# MCAN register map
Vendor: Texas Instruments
Registers are 32-bit, access per field, no defined reset value unless marked. A register's access mark holds for its fields unless they carry their own. Offsets are as the file gives them; [hi:lo] are bit positions.

## MCAN (part 2 of 2)
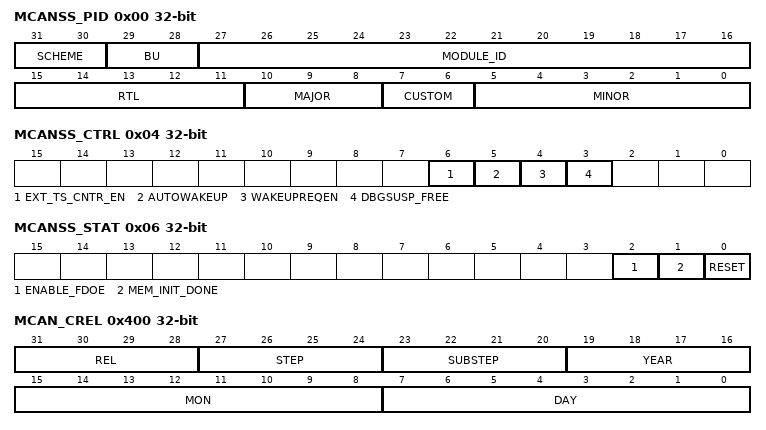
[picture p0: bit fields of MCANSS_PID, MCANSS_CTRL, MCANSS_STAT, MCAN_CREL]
0x00 MCANSS_PID ro — MCAN Subsystem Revision Register
  [31:30] SCHEME — PID Register Scheme
  [29:28] BU — Business Unit: 0x2 = Processors
  [27:16] MODULE_ID — Module Identification Number
  [15:11] RTL — RTL revision. Will vary depending on release
  [10:8] MAJOR — Major Revision of the MCAN Subsystem
  [7:6] CUSTOM — Custom Value
  [5:0] MINOR — Minor Revision of the MCAN Subsystem
0x04 MCANSS_CTRL — MCAN Subsystem Control Register
  [6] EXT_TS_CNTR_EN rw — External Timestamp Counter Enable. #br# 0 External timestamp counter disabled #br# 1 External timestamp counter enabled
  [5] AUTOWAKEUP rw — Automatic Wakeup Enable. Enables the MCANSS to automatically clear the MCAN CCCR.INIT bit, fully waking the MCAN up, on an enabled wakeup request. #br# 0 Disable the automatic write to CCCR.INIT #br# 1 Enable the automatic write to CCCR.INIT
  [4] WAKEUPREQEN rw — Wakeup Request Enable. Enables the MCANSS to wakeup on CAN RXD activity. #br# 0 Disable wakeup request #br# 1 Enables wakeup request
  [3] DBGSUSP_FREE rw — Debug Suspend Free Bit. Enables debug suspend. #br# 0 Disable debug suspend #br# 1 Enable debug suspend
0x06 MCANSS_STAT ro — MCAN Subsystem Status Register
  [2] ENABLE_FDOE — Flexible Datarate Operation Enable. Determines whether CAN FD operation may be enabled via the MCAN core CCCR.FDOE bit (bit 8) or if only standard CAN operation is possible with this instance of the MCAN. #br# 0 MCAN is only capable of standard CAN communication #br# 1 MCAN may be configured to perform CAN FD communication
  [1] MEM_INIT_DONE — Memory Initialization Done. #br# 0 Message RAM initialization is in progress #br# 1 Message RAM is initialized for use
  [0] RESET — Soft Reset Status. #br# 0 Not in reset #br# 1 Reset is in progress
0x0C MCANSS_ICS — MCAN Subsystem Interrupt Clear Shadow Register
  [0] EXT_TS_CNTR_OVFL rw — External Timestamp Counter Overflow Interrupt Status Clear. Reads always return a 0. #br# 0 Write of '0' has no effect #br# 1 Write of '1' clears the MCANSS_IRS.EXT_TS_CNTR_OVFL bit
0x10 MCANSS_IRS — MCAN Subsystem Interrupt Raw Satus Register
  [0] EXT_TS_CNTR_OVFL rw — External Timestamp Counter Overflow Interrupt Status. This bit is set by HW or by a SW write of '1'. To clear, use the MCANSS_ICS.EXT_TS_CNTR_OVFL bit. #br# 0 External timestamp counter has not overflowed #br# 1 External timestamp counter has overflowed #br# #br#When this bit is set to '1' by HW or SW, the MCANSS_EXT_TS_UNSERVICED_INTR_CNTR.EXT_TS_INTR_CNTR bit field will increment by 1.
0x14 MCANSS_IECS — MCAN Subsystem Interrupt Enable Clear Shadow Register
  [0] EXT_TS_CNTR_OVFL rw — External Timestamp Counter Overflow Interrupt Enable Clear. Reads always return a 0. #br# 0 Write of '0' has no effect #br# 1 Write of '1' clears the MCANSS_IES.EXT_TS_CNTR_OVFL bit
0x18 MCANSS_IE — MCAN Subsystem Interrupt Enable Register
  [0] EXT_TS_CNTR_OVFL rw — External Timestamp Counter Overflow Interrupt Enable. A write of '0' has no effect. A write of '1' sets the MCANSS_IES.EXT_TS_CNTR_OVFL bit.
0x1C MCANSS_IES ro — MCAN Subsystem Interrupt Enable Status
  [0] EXT_TS_CNTR_OVFL — External Timestamp Counter Overflow Interrupt Enable Status. To set, use the CANSS_IE.EXT_TS_CNTR_OVFL bit. To clear, use the MCANSS_IECS.EXT_TS_CNTR_OVFL bit. #br# 0 External timestamp counter overflow interrupt is not enabled #br# 1 External timestamp counter overflow interrupt is enabled
0x20 MCANSS_EOI — MCAN Subsystem End of Interrupt
  [7:0] EOI rw — End of Interrupt. A write to this register will clear the associated interrupt. If the unserviced interrupt counter is > 1, another interrupt is generated. #br# 0x00 External TS Interrupt is cleared #br# 0x01 MCAN[0] interrupt is cleared #br# 0x02 MCAN[1] interrupt is cleared #br# Other writes are ignored.
0x24 MCANSS_EXT_TS_PRESCALER — MCAN Subsystem External Timestamp Prescaler 0
  [23:0] PRESCALER rw — External Timestamp Prescaler Reload Value. The external timestamp count rate is the host (system) clock rate divided by this value, except in the case of 0. A zero value in this bit field will act identically to a value of 0x000001.
0x28 MCANSS_EXT_TS_UNSERVICED_INTR_CNTR ro — MCAN Subsystem External Timestamp Unserviced Interrupts Counter
  [4:0] EXT_TS_INTR_CNTR — External Timestamp Counter Unserviced Rollover Interrupts. If this value is > 1, an MCANSS_EOI write of '1' to bit 0 will issue another interrupt. #br# #br#The status of this bit field is affected by the MCANSS_IRS.EXT_TS_CNTR_OVFL bit field.
0x400 MCAN_CREL ro — MCAN Core Release Register
  [31:28] REL — Core Release. One digit, BCD-coded.
  [27:24] STEP — Step of Core Release. One digit, BCD-coded.
  [23:20] SUBSTEP — Sub-Step of Core Release. One digit, BCD-coded.
  [19:16] YEAR — Time Stamp Year. One digit, BCD-coded.
  [15:8] MON — Time Stamp Month. Two digits, BCD-coded.
  [7:0] DAY — Time Stamp Day. Two digits, BCD-coded.
0x404 MCAN_ENDN ro — MCAN Endian Register
  [31:0] ETV — Endianess Test Value. Reading the constant value maintained in this register allows software to determine the endianess of the host CPU.
0x408 MCAN_CUST ro — MCAN Customer Register
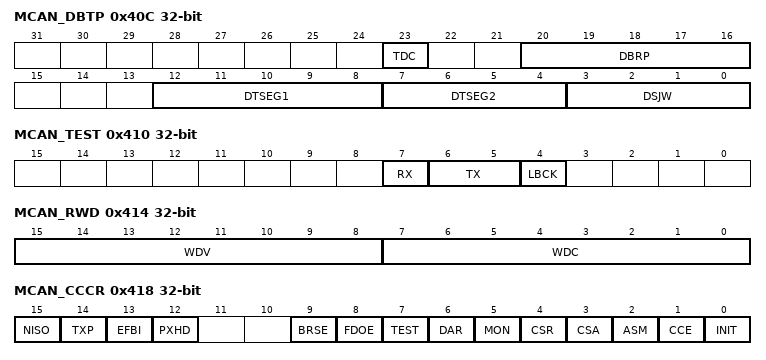
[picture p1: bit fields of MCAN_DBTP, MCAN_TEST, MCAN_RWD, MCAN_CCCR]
0x40C MCAN_DBTP — This register is only writable if bits CCCR.CCE and CCCR.INIT are set. The CAN bit time may be programed in the range of 4 to 49 time quanta. The CAN time quantum may be programmed in the range of 1 to 32 m_can_cclk periods. tq = (DBRP + 1) mtq. #br# #br#DTSEG1 is the sum of Prop_Seg and Phase_Seg1. DTSEG2 is Phase_Seg2. #br# #br#Therefore the length of the bit time is (programmed values) [DTSEG1 + DTSEG2 + 3] tq or (functional values) [Sync_Seg + Prop_Seg + Phase_Seg1 + Phase_Seg2] tq. #br# #br#The Information Processing Time (IPT) is zero, meaning the data for the next bit is available at the first clock edge after the sample point.
  [23] TDC rw — Transmitter Delay Compensation #br# 0 Transmitter Delay Compensation disabled #br# 1 Transmitter Delay Compensation enabled #br# #br#+I107
  [20:16] DBRP rw — Data Bit Rate Prescaler. The value by which the oscillator frequency is divided for generating the bit time quanta. The bit time is built up from a multiple of this quanta. Valid values for the Bit Rate Prescaler are 0 to 31. The actual interpretation by the hardware of this value is such that one more than the value programmed here is used. #br# #br#Qualified Write is possible only with CCCR.CCE='1' and CCCR.INIT='1'.
  [12:8] DTSEG1 rw — Data Time Segment Before Sample Point. Valid values are 0 to 31. The actual interpretation by the hardware of this value is such that one more than the programmed value is used. #br# #br#Qualified Write is possible only with CCCR.CCE='1' and CCCR.INIT='1'.
  [7:4] DTSEG2 rw — Data Time Segment After Sample Point. Valid values are 0 to 15. The actual interpretation by the hardware of this value is such that one more than the programmed value is used. #br# #br#Qualified Write is possible only with CCCR.CCE='1' and CCCR.INIT='1'.
  [3:0] DSJW rw — Data Resynchronization Jump Width. Valid values are 0 to 15. The actual interpretation by the hardware of this value is such that one more than the value programmed here is used. #br# #br#Qualified Write is possible only with CCCR.CCE='1' and CCCR.INIT='1'.
0x410 MCAN_TEST — Write access to the Test Register has to be enabled by setting bit CCCR.TEST to '1'. All Test Register functions are set to their reset values when bit CCCR.TEST is reset. #br# #br#Loop Back Mode and software control of the internal CAN TX pin are hardware test modes. Programming of #br#TX != "00" may disturb the message transfer on the CAN bus.
  [7] RX ro — Receive Pin. Monitors the actual value of the CAN receive pin. #br# 0 The CAN bus is dominant (CAN RX pin = '0') #br# 1 The CAN bus is recessive (CAN RX pin = '1')
  [6:5] TX rw — Control of Transmit Pin #br# 00 CAN TX pin controlled by the CAN Core, updated at the end of the CAN bit time #br# 01 Sample Point can be monitored at CAN TX pin #br# 10 Dominant ('0') level at CAN TX pin #br# 11 Recessive ('1') at CAN TX pin #br# #br#Qualified Write is possible only with CCCR.CCE='1' and CCCR.INIT='1'.
  [4] LBCK rw — Loop Back Mode #br# 0 Reset value, Loop Back Mode is disabled #br# 1 Loop Back Mode is enabled #br# #br#Qualified Write is possible only with CCCR.CCE='1' and CCCR.INIT='1'.
0x414 MCAN_RWD — MCAN RAM Watchdog
  [15:8] WDV ro — Watchdog Value. Actual Message RAM Watchdog Counter Value. #br# #br#The RAM Watchdog monitors the READY output of the Message RAM. A Message RAM access via the MCAN's Generic Controller Interface starts the Message RAM Watchdog Counter with the value configured by the WDC field. The counter is reloaded with WDC when the Message RAM signals successful completion by activating its READY output. In case there is no response from the Message RAM until the counter has counted down to zero, the counter stops and interrupt flag MCAN_IR.WDI is set. The RAM Watchdog Counter is clocked by the host (system) clock.
  [7:0] WDC rw — Watchdog Configuration. Start value of the Message RAM Watchdog Counter. With the reset value of "00" the counter is disabled. #br# #br#Qualified Write is possible only with CCCR.CCE='1' and CCCR.INIT='1'.
0x418 MCAN_CCCR — MCAN CC Control Register
  [15] NISO rw — Non ISO Operation. If this bit is set, the MCAN uses the CAN FD frame format as specified by the Bosch CAN FD Specification V1.0. #br# 0 CAN FD frame format according to ISO 11898-1:2015 #br# 1 CAN FD frame format according to Bosch CAN FD Specification V1.0
  [14] TXP rw — Transmit Pause. If this bit is set, the MCAN pauses for two CAN bit times before starting the next transmission after itself has successfully transmitted a frame. #br# 0 Transmit pause disabled #br# 1 Transmit pause enabled #br# #br#Qualified Write is possible only with CCCR.CCE='1' and CCCR.INIT='1'.
  [13] EFBI rw — Edge Filtering during Bus Integration #br# 0 Edge filtering disabled #br# 1 Two consecutive dominant tq required to detect an edge for hard synchronization #br# #br#Qualified Write is possible only with CCCR.CCE='1' and CCCR.INIT='1'.
  [12] PXHD rw — Protocol Exception Handling Disable #br# 0 Protocol exception handling enabled #br# 1 Protocol exception handling disabled #br#Note: When protocol exception handling is disabled, the MCAN will transmit an error frame when it detects a protocol exception condition. #br# #br#Qualified Write is possible only with CCCR.CCE='1' and CCCR.INIT='1'.
  [9] BRSE rw — Bit Rate Switch Enable #br# 0 Bit rate switching for transmissions disabled #br# 1 Bit rate switching for transmissions enabled #br#Note: When CAN FD operation is disabled FDOE = '0', BRSE is not evaluated. #br# #br#Qualified Write is possible only with CCCR.CCE='1' and CCCR.INIT='1'.
  [8] FDOE rw — Flexible Datarate Operation Enable #br# 0 FD operation disabled #br# 1 FD operation enabled #br# #br#Qualified Write is possible only with CCCR.CCE='1' and CCCR.INIT='1'.
  [7] TEST rw — Test Mode Enable #br# 0 Normal operation, register TEST holds reset values #br# 1 Test Mode, write access to register TEST enabled #br# #br#Qualified Write 1 to Set is possible only with CCCR.CCE='1' and CCCR.INIT='1'.
  [6] DAR rw — Disable Automatic Retransmission #br# 0 Automatic retransmission of messages not transmitted successfully enabled #br# 1 Automatic retransmission disabled #br# #br#Qualified Write is possible only with CCCR.CCE='1' and CCCR.INIT='1'.
  [5] MON rw — Bus Monitoring Mode. Bit MON can only be set by SW when both CCE and INIT are set to '1'. The bit can be reset by SW at any time. #br# 0 Bus Monitoring Mode is disabled #br# 1 Bus Monitoring Mode is enabled #br# #br#Qualified Write 1 to Set is possible only with CCCR.CCE='1' and CCCR.INIT='1'.
  [4] CSR rw — Clock Stop Request #br# 0 No clock stop is requested #br# 1 Clock stop requested. When clock stop is requested, first INIT and then CSA will be set after all pending transfer requests have been completed and the CAN bus reached idle.
  [3] CSA ro — Clock Stop Acknowledge #br# 0 No clock stop acknowledged #br# 1 MCAN may be set in power down by stopping the Host and CAN clocks
  [2] ASM rw — Restricted Operation Mode. Bit ASM can only be set by SW when both CCE and INIT are set to '1'. The bit can be reset by SW at any time. #br# 0 Normal CAN operation #br# 1 Restricted Operation Mode active #br# #br#Qualified Write 1 to Set is possible only with CCCR.CCE='1' and CCCR.INIT='1'.
  [1] CCE rw — Configuration Change Enable #br# 0 The CPU has no write access to the protected configuration registers #br# 1 The CPU has write access to the protected configuration registers (while CCCR.INIT = '1') #br# #br#Qualified Write is possible only with CCCR.CCE='1' and CCCR.INIT='1'.
  [0] INIT rw — Initialization #br# 0 Normal Operation #br# 1 Initialization is started #br#Note: Due to the synchronization mechanism between the two clock domains, there may be a delay until the value written to INIT can be read back. Therefore the programmer has to assure that the previous value written to INIT has been accepted by reading INIT before setting INIT to a new value.
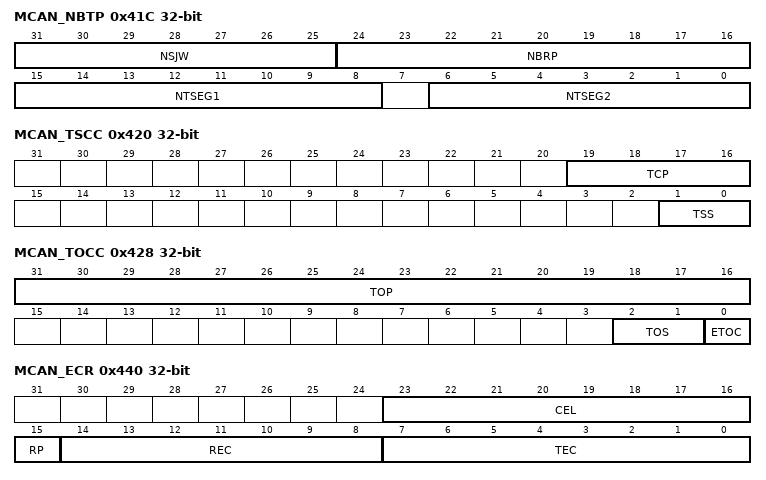
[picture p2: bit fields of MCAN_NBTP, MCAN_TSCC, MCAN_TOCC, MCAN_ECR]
0x41C MCAN_NBTP — This register is only writable if bits CCCR.CCE and CCCR.INIT are set. The CAN bit time may be programed in the range of 4 to 385 time quanta. The CAN time quantum may be programmed in the range of 1 to 512 m_can_cclk periods. tq = (NBRP + 1) mtq. #br# #br#NTSEG1 is the sum of Prop_Seg and Phase_Seg1. NTSEG2 is Phase_Seg2. #br# #br#Therefore the length of the bit time is (programmed values) [NTSEG1 + NTSEG2 + 3] tq or (functional values) [Sync_Seg + Prop_Seg + Phase_Seg1 + Phase_Seg2] tq. #br# #br#The Information Processing Time (IPT) is zero, meaning the data for the next bit is available at the first clock edge after the sample point. #br# #br#Note: With a CAN clock of 8 MHz, the reset value of 0x06000A03 configures the MCAN for a bit rate of 500 kBit/s.
  [31:25] NSJW rw — Nominal (Re)Synchronization Jump Width. Valid values are 0 to 127. The actual interpretation by the hardware of this value is such that one more than the value programmed here is used. #br# #br#Qualified Write is possible only with CCCR.CCE='1' and CCCR.INIT='1'.
  [24:16] NBRP rw — Nominal Bit Rate Prescaler. The value by which the oscillator frequency is divided for generating the bit time quanta. The bit time is built up from a multiple of this quanta. Valid values for the Bit Rate Prescaler are 0 to 511. The actual interpretation by the hardware of this value is such that one more than the value programmed here is used. #br# #br#Qualified Write is possible only with CCCR.CCE='1' and CCCR.INIT='1'.
  [15:8] NTSEG1 rw — Nominal Time Segment Before Sample Point. Valid values are 1 to 255. The actual interpretation by the hardware of this value is such that one more than the programmed value is used. #br# #br#Qualified Write is possible only with CCCR.CCE='1' and CCCR.INIT='1'.
  [6:0] NTSEG2 rw — Nominal Time Segment After Sample Point. Valid values are 1 to 127. The actual interpretation by the hardware of this value is such that one more than the programmed value is used. #br# #br#Qualified Write is possible only with CCCR.CCE='1' and CCCR.INIT='1'.
0x420 MCAN_TSCC — MCAN Timestamp Counter Configuration
  [19:16] TCP rw — Timestamp Counter Prescaler. Configures the timestamp and timeout counters time unit in multiples of CAN bit times. Valid values are 0 to 15. The actual interpretation by the hardware of this value is such that one more than the value programmed here is used. #br# #br#Note: With CAN FD an external counter is required for timestamp generation (TSS = "10"). #br# #br#Qualified Write is possible only with CCCR.CCE='1' and CCCR.INIT='1'.
  [1:0] TSS rw — Timestamp Select #br# 00 Timestamp counter value always 0x0000 #br# 01 Timestamp counter value incremented according to TCP #br# 10 External timestamp counter value used #br# 11 Same as "00" #br# #br#Qualified Write is possible only with CCCR.CCE='1' and CCCR.INIT='1'.
0x424 MCAN_TSCV — MCAN Timestamp Counter Value
  [15:0] TSC rw — Timestamp Counter. The internal/external Timestamp Counter value is captured on start of frame (both Rx and Tx). When TSCC.TSS = "01", the Timestamp Counter is incremented in multiples of CAN bit times, [1...16], depending on the configuration of TSCC.TCP. A wrap around sets interrupt flag IR.TSW. Write access resets the counter to zero. When TSCC.TSS = "10", TSC reflects the External Timestamp Counter value, and a write access has no impact. #br# #br#Note: A "wrap around" is a change of the Timestamp Counter value from non-zero to zero not #br#caused by write access to MCAN_TSCV.
0x428 MCAN_TOCC — MCAN Timeout Counter Configuration
  [31:16] TOP rw — Timeout Period. Start value of the Timeout Counter (down-counter). Configures the Timeout Period. #br# #br#Qualified Write is possible only with CCCR.CCE='1' and CCCR.INIT='1'.
  [2:1] TOS rw — Timeout Select. When operating in Continuous mode, a write to TOCV presets the counter to the value configured by TOCC.TOP and continues down-counting. When the Timeout Counter is controlled by one of the FIFOs, an empty FIFO presets the counter to the value configured by TOCC.TOP. Down-counting is started when the first FIFO element is stored. #br# 00 Continuous operation #br# 01 Timeout controlled by Tx Event FIFO #br# 10 Timeout controlled by Rx FIFO 0 #br# 11 Timeout controlled by Rx FIFO 1 #br# #br#Qualified Write is possible only with CCCR.CCE='1' and CCCR.INIT='1'.
  [0] ETOC rw — Enable Timeout Counter #br# 0 Timeout Counter disabled #br# 1 Timeout Counter enabled #br# #br#Qualified Write is possible only with CCCR.CCE='1' and CCCR.INIT='1'.
0x42C MCAN_TOCV — MCAN Timeout Counter Value
  [15:0] TOC rw — Timeout Counter. The Timeout Counter is decremented in multiples of CAN bit times, [1...16], depending on the configuration of TSCC.TCP. When decremented to zero, interrupt flag IR.TOO is set and the Timeout Counter is stopped. Start and reset/restart conditions are configured via TOCC.TOS.
0x440 MCAN_ECR ro — MCAN Error Counter Register
  [23:16] CEL — CAN Error Logging. The counter is incremented each time when a CAN protocol error causes the Transmit Error Counter or the Receive Error Counter to be incremented. It is reset by read access to CEL. The counter stops at 0xFF; the next increment of TEC or REC sets interrupt flag IR.ELO. #br# #br#Note: When CCCR.ASM is set, the CAN protocol controller does not increment TEC and REC when a CAN protocol error is detected, but CEL is still incremented.
  [15] RP — Receive Error Passive #br# 0 The Receive Error Counter is below the error passive level of 128 #br# 1 The Receive Error Counter has reached the error passive level of 128
  [14:8] REC — Receive Error Counter. Actual state of the Receive Error Counter, values between 0 and 127. #br# #br#Note: When CCCR.ASM is set, the CAN protocol controller does not increment TEC and REC when a CAN protocol error is detected, but CEL is still incremented.
  [7:0] TEC — Transmit Error Counter. Actual state of the Transmit Error Counter, values between 0 and 255. #br# #br#Note: When CCCR.ASM is set, the CAN protocol controller does not increment TEC and REC when a CAN protocol error is detected, but CEL is still incremented.
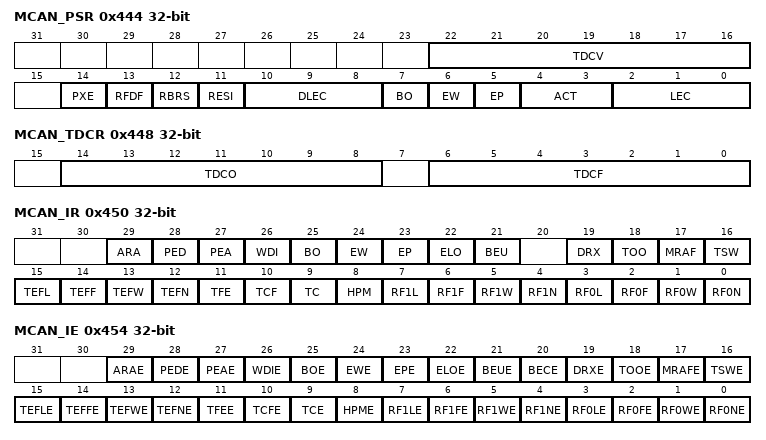
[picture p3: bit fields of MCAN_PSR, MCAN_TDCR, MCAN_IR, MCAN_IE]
0x444 MCAN_PSR ro — MCAN Protocol Status Register
  [22:16] TDCV — Transmitter Delay Compensation Value. Position of the secondary sample point, defined by the sum of the measured delay from the internal CAN TX signal to the internal CAN RX signal and TDCR.TDCO. The SSP position is, in the data phase, the number of mtq between the start of the transmitted bit and the secondary sample point. Valid values are 0 to 127 mtq.
  [14] PXE — Protocol Exception Event #br# 0 No protocol exception event occurred since last read access #br# 1 Protocol exception event occurred
  [13] RFDF — Received a CAN FD Message. This bit is set independent of acceptance filtering. #br# 0 Since this bit was reset by the CPU, no CAN FD message has been received #br# 1 Message in CAN FD format with FDF flag set has been received
  [12] RBRS — BRS Flag of Last Received CAN FD Message. This bit is set together with RFDF, independent of acceptance filtering. #br# 0 Last received CAN FD message did not have its BRS flag set #br# 1 Last received CAN FD message had its BRS flag set
  [11] RESI — ESI Flag of Last Received CAN FD Message. This bit is set together with RFDF, independent of acceptance filtering. #br# 0 Last received CAN FD message did not have its ESI flag set #br# 1 Last received CAN FD message had its ESI flag set
  [10:8] DLEC — Data Phase Last Error Code. Type of last error that occurred in the data phase of a CAN FD format frame with its BRS flag set. Coding is the same as for LEC. This field will be cleared to zero when a CAN FD format frame with its BRS flag set has been transferred (reception or transmission) without error.
  [7] BO — Bus_Off Status #br# 0 The M_CAN is not Bus_Off #br# 1 The M_CAN is in Bus_Off state
  [6] EW — Warning Status #br# 0 Both error counters are below the Error_Warning limit of 96 #br# 1 At least one of error counter has reached the Error_Warning limit of 96
  [5] EP — Error Passive #br# 0 The M_CAN is in the Error_Active state. It normally takes part in bus communication and sends an active error flag when an error has been detected #br# 1 The M_CAN is in the Error_Passive state
  [4:3] ACT — Node Activity. Monitors the module's CAN communication state. #br# 00 Synchronizing - node is synchronizing on CAN communication #br# 01 Idle - node is neither receiver nor transmitter #br# 10 Receiver - node is operating as receiver #br# 11 Transmitter - node is operating as transmitter #br# #br#Note: ACT is set to "00" by a Protocol Exception Event.
  [2:0] LEC — Last Error Code. The LEC indicates the type of the last error to occur on the CAN bus. This field will be cleared to '0' when a message has been transferred (reception or transmission) without error. #br# 0 No Error: No error occurred since LEC has been reset by successful reception or transmission. #br# 1 Stuff Error: More than 5 equal bits in a sequence have occurred in a part of a received message where this is not allowed. #br# 2 Form Error: A fixed format part of a received frame has the wrong format. #br# 3 AckError: The message transmitted by the MCAN was not acknowledged by another node. #br# 4 Bit1Error: During the transmission of a message (with the exception of the arbitration field), the device wanted to send a recessive level (bit of logical value '1'), but the monitored bus value was dominant. #br# 5 Bit0Error: During the transmission of a message (or acknowledge bit, or active error flag, or overload flag), the device wanted to send a dominant level (data or identifier bit logical value '0'), but the monitored bus value was recessive. During Bus_Off recovery this status is set each time a sequence of 11 recessive bits has been monitored. This enables the CPU to monitor the proceeding of the Bus_Off recovery sequence (indicating the bus is not stuck at dominant or continuously disturbed). #br# 6 CRCError: The CRC check sum of a received message was incorrect. The CRC of an incoming message does not match with the CRC calculated from the received data. #br# 7 NoChange: Any read access to the Protocol Status Register re-initializes the LEC to '7'. When the LEC shows the value '7', no CAN bus event was detected since the last CPU read access to the Protocol Status Register. #br# #br#Note: When a frame in CAN FD format has reached the data phase with BRS flag set, the next CAN event (error or valid frame) will be shown in DLEC instead of LEC. An error in a fixed stuff bit of a CAN FD CRC sequence will be shown as a Form Error, not Stuff Error. Note: The Bus_Off recovery sequence (see ISO 11898-1:2015) cannot be shortened by setting or resetting CCCR.INIT. If the device goes Bus_Off, it will set CCCR.INIT of its own accord, stopping all bus activities. Once CCCR.INIT has been cleared by the CPU, the device will then wait for 129 occurrences of Bus Idle (129 * 11 consecutive recessive bits) before resuming normal operation. At the end of the Bus_Off recovery sequence, the Error Management Counters will be reset. During the waiting time after the resetting of CCCR.INIT, each time a sequence of 11 recessive bits has been monitored, a Bit0Error code is written to PSR.LEC, enabling the CPU to readily check up whether the CAN bus is stuck at dominant or continuously disturbed and to monitor the Bus_Off recovery sequence. ECR.REC is used to count these sequences.
0x448 MCAN_TDCR — MCAN Transmitter Delay Compensation Register
  [14:8] TDCO rw — Transmitter Delay Compensation Offset. Offset value defining the distance between the measured delay from the internal CAN TX signal to the internal CAN RX signal and the secondary sample point. Valid values are 0 to 127 mtq. #br# #br#Qualified Write is possible only with CCCR.CCE='1' and CCCR.INIT='1'.
  [6:0] TDCF rw — Transmitter Delay Compensation Filter Window Length. Defines the minimum value for the SSP position, dominant edges on the internal CAN RX signal that would result in an earlier SSP position are ignored for transmitter delay measurement. The feature is enabled when TDCF is configured to a value greater than TDCO. Valid values are 0 to 127 mtq. #br# #br#Qualified Write is possible only with CCCR.CCE='1' and CCCR.INIT='1'.
0x450 MCAN_IR — The flags are set when one of the listed conditions is detected (edge-sensitive). The flags remain set until the Host clears them. Aflag is cleared by writing a '1' to the corresponding bit position. Writing a '0' has no effect. Ahard reset will clear the register. The configuration of IE controls whether an interrupt is generated. The configuration of ILS controls on which interrupt line an interrupt is signalled.
  [29] ARA rw — Access to Reserved Address #br# 0 No access to reserved address occurred #br# 1 Access to reserved address occurred
  [28] PED rw — Protocol Error in Data Phase (Data Bit Time is used) #br# 0 No protocol error in data phase #br# 1 Protocol error in data phase detected (PSR.DLEC != 0,7)
  [27] PEA rw — Protocol Error in Arbitration Phase (Nominal Bit Time is used) #br# 0 No protocol error in arbitration phase #br# 1 Protocol error in arbitration phase detected (PSR.LEC != 0,7)
  [26] WDI rw — Watchdog Interrupt #br# 0 No Message RAM Watchdog event occurred #br# 1 Message RAM Watchdog event due to missing READY
  [25] BO rw — Bus_Off Status #br# 0 Bus_Off status unchanged #br# 1 Bus_Off status changed
  [24] EW rw — Warning Status #br# 0 Error_Warning status unchanged #br# 1 Error_Warning status changed
  [23] EP rw — Error Passive #br# 0 Error_Passive status unchanged #br# 1 Error_Passive status changed
  [22] ELO rw — Error Logging Overflow #br# 0 CAN Error Logging Counter did not overflow #br# 1 Overflow of CAN Error Logging Counter occurred
  [21] BEU rw — Bit Error Uncorrected. Message RAM bit error detected, uncorrected. This bit is set when a double bit error is detected by the ECC aggregator attached to the Message RAM. An uncorrected Message RAM bit error sets CCCR.INIT to '1'. This is done to avoid transmission of corrupted data. #br# 0 No bit error detected when reading from Message RAM #br# 1 Bit error detected, uncorrected (e.g. parity logic)
  [19] DRX rw — Message Stored to Dedicated Rx Buffer. The flag is set whenever a received message has been stored into a dedicated Rx Buffer. #br# 0 No Rx Buffer updated #br# 1 At least one received message stored into an Rx Buffer
  [18] TOO rw — Timeout Occurred #br# 0 No timeout #br# 1 Timeout reached
  [17] MRAF rw — Message RAM Access Failure. The flag is set, when the Rx Handler: #br# - has not completed acceptance filtering or storage of an accepted message until the arbitration field of the following message has been received. In this case acceptance filtering or message storage is aborted and the Rx Handler starts processing of the following message. #br# - was not able to write a message to the Message RAM. In this case message storage is aborted. #br# #br#In both cases the FIFO put index is not updated resp. the New Data flag for a dedicated Rx Buffer is not set, a partly stored message is overwritten when the next message is stored to this location. #br# #br#The flag is also set when the Tx Handler was not able to read a message from the Message RAM in time. In this case message transmission is aborted. In case of a Tx Handler access failure the MCAN is switched into Restricted Operation Mode. To leave Restricted Operation Mode, the Host CPU has to reset CCCR.ASM. #br# 0 No Message RAM access failure occurred #br# 1 Message RAM access failure occurred
  [16] TSW rw — Timestamp Wraparound #br# 0 No timestamp counter wrap-around #br# 1 Timestamp counter wrapped around
  [15] TEFL rw — Tx Event FIFO Element Lost #br# 0 No Tx Event FIFO element lost #br# 1 Tx Event FIFO element lost, also set after write attempt to Tx Event FIFO of size zero
  [14] TEFF rw — Tx Event FIFO Full #br# 0 Tx Event FIFO not full #br# 1 Tx Event FIFO full
  [13] TEFW rw — Tx Event FIFO Watermark Reached #br# 0 Tx Event FIFO fill level below watermark #br# 1 Tx Event FIFO fill level reached watermark
  [12] TEFN rw — Tx Event FIFO New Entry #br# 0 Tx Event FIFO unchanged #br# 1 Tx Handler wrote Tx Event FIFO element
  [11] TFE rw — Tx FIFO Empty #br# 0 Tx FIFO non-empty #br# 1 Tx FIFO empty
  [10] TCF rw — Transmission Cancellation Finished #br# 0 No transmission cancellation finished #br# 1 Transmission cancellation finished
  [9] TC rw — Transmission Completed #br# 0 No transmission completed #br# 1 Transmission completed
  [8] HPM rw — High Priority Message #br# 0 No high priority message received #br# 1 High priority message received
  [7] RF1L rw — Rx FIFO 1 Message Lost #br# 0 No Rx FIFO 1 message lost #br# 1 Rx FIFO 1 message lost, also set after write attempt to Rx FIFO 1 of size zero
  [6] RF1F rw — Rx FIFO 1 Full #br# 0 Rx FIFO 1 not full #br# 1 Rx FIFO 1 full
  [5] RF1W rw — Rx FIFO 1 Watermark Reached #br# 0 Rx FIFO 1 fill level below watermark #br# 1 Rx FIFO 1 fill level reached watermark
  [4] RF1N rw — Rx FIFO 1 New Message #br# 0 No new message written to Rx FIFO 1 #br# 1 New message written to Rx FIFO 1
  [3] RF0L rw — Rx FIFO 0 Message Lost #br# 0 No Rx FIFO 0 message lost #br# 1 Rx FIFO 0 message lost, also set after write attempt to Rx FIFO 0 of size zero
  [2] RF0F rw — Rx FIFO 0 Full #br# 0 Rx FIFO 0 not full #br# 1 Rx FIFO 0 full
  [1] RF0W rw — Rx FIFO 0 Watermark Reached #br# 0 Rx FIFO 0 fill level below watermark #br# 1 Rx FIFO 0 fill level reached watermark
  [0] RF0N rw — Rx FIFO 0 New Message #br# 0 No new message written to Rx FIFO 0 #br# 1 New message written to Rx FIFO 0
0x454 MCAN_IE — MCAN Interrupt Enable
  [29] ARAE rw — Access to Reserved Address Enable
  [28] PEDE rw — Protocol Error in Data Phase Enable
  [27] PEAE rw — Protocol Error in Arbitration Phase Enable
  [26] WDIE rw — Watchdog Interrupt Enable
  [25] BOE rw — Bus_Off Status Enable
  [24] EWE rw — Warning Status Enable
  [23] EPE rw — Error Passive Enable
  [22] ELOE rw — Error Logging Overflow Enable
  [21] BEUE rw — Bit Error Uncorrected Enable
  [20] BECE rw — Bit Error Corrected Enable #br# #br#A separate interrupt line reserved for corrected bit errors is provided via the MCAN_ERROR_REGS. It advised for the user to use these registers and leave this bit cleared to '0'.
  [19] DRXE rw — Message Stored to Dedicated Rx Buffer Enable
  [18] TOOE rw — Timeout Occurred Enable
  [17] MRAFE rw — Message RAM Access Failure Enable
  [16] TSWE rw — Timestamp Wraparound Enable
  [15] TEFLE rw — Tx Event FIFO Element Lost Enable
  [14] TEFFE rw — Tx Event FIFO Full Enable
  [13] TEFWE rw — Tx Event FIFO Watermark Reached Enable
  [12] TEFNE rw — Tx Event FIFO New Entry Enable
  [11] TFEE rw — Tx FIFO Empty Enable
  [10] TCFE rw — Transmission Cancellation Finished Enable
  [9] TCE rw — Transmission Completed Enable
  [8] HPME rw — High Priority Message Enable
  [7] RF1LE rw — Rx FIFO 1 Message Lost Enable
  [6] RF1FE rw — Rx FIFO 1 Full Enable
  [5] RF1WE rw — Rx FIFO 1 Watermark Reached Enable
  [4] RF1NE rw — Rx FIFO 1 New Message Enable
  [3] RF0LE rw — Rx FIFO 0 Message Lost Enable
  [2] RF0FE rw — Rx FIFO 0 Full Enable
  [1] RF0WE rw — Rx FIFO 0 Watermark Reached Enable
  [0] RF0NE rw — Rx FIFO 0 New Message Enable
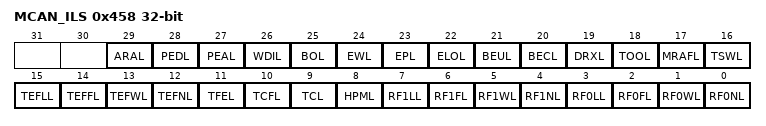
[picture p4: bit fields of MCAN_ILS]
0x458 MCAN_ILS — The Interrupt Line Select register assigns an interrupt generated by a specific interrupt flag from the Interrupt Register to one of the two module interrupt lines. For interrupt generation the respective interrupt line has to be enabled via ILE.EINT0 and ILE.EINT1.
  [29] ARAL rw — Access to Reserved Address Line #br# 0 Interrupt source is assigned to Interrupt Line 0 #br# 1 Interrupt source is assigned to Interrupt Line 1
  [28] PEDL rw — Protocol Error in Data Phase Line #br# 0 Interrupt source is assigned to Interrupt Line 0 #br# 1 Interrupt source is assigned to Interrupt Line 1
  [27] PEAL rw — Protocol Error in Arbitration Phase Line #br# 0 Interrupt source is assigned to Interrupt Line 0 #br# 1 Interrupt source is assigned to Interrupt Line 1
  [26] WDIL rw — Watchdog Interrupt Line #br# 0 Interrupt source is assigned to Interrupt Line 0 #br# 1 Interrupt source is assigned to Interrupt Line 1
  [25] BOL rw — Bus_Off Status Line #br# 0 Interrupt source is assigned to Interrupt Line 0 #br# 1 Interrupt source is assigned to Interrupt Line 1
  [24] EWL rw — Warning Status Line #br# 0 Interrupt source is assigned to Interrupt Line 0 #br# 1 Interrupt source is assigned to Interrupt Line 1
  [23] EPL rw — Error Passive Line #br# 0 Interrupt source is assigned to Interrupt Line 0 #br# 1 Interrupt source is assigned to Interrupt Line 1
  [22] ELOL rw — Error Logging Overflow Line #br# 0 Interrupt source is assigned to Interrupt Line 0 #br# 1 Interrupt source is assigned to Interrupt Line 1
  [21] BEUL rw — Bit Error Uncorrected Line #br# 0 Interrupt source is assigned to Interrupt Line 0 #br# 1 Interrupt source is assigned to Interrupt Line 1
  [20] BECL rw — Bit Error Corrected Line #br# #br#A separate interrupt line reserved for corrected bit errors is provided via the MCAN_ERROR_REGS. It advised for the user to use these registers and leave the MCAN_IE.BECE bit cleared to '0' (disabled), thereby relegating this bit to not applicable.
  [19] DRXL rw — Message Stored to Dedicated Rx Buffer Line #br# 0 Interrupt source is assigned to Interrupt Line 0 #br# 1 Interrupt source is assigned to Interrupt Line 1
  [18] TOOL rw — Timeout Occurred Line #br# 0 Interrupt source is assigned to Interrupt Line 0 #br# 1 Interrupt source is assigned to Interrupt Line 1
  [17] MRAFL rw — Message RAM Access Failure Line #br# 0 Interrupt source is assigned to Interrupt Line 0 #br# 1 Interrupt source is assigned to Interrupt Line 1
  [16] TSWL rw — Timestamp Wraparound Line #br# 0 Interrupt source is assigned to Interrupt Line 0 #br# 1 Interrupt source is assigned to Interrupt Line 1
  [15] TEFLL rw — Tx Event FIFO Element Lost Line #br# 0 Interrupt source is assigned to Interrupt Line 0 #br# 1 Interrupt source is assigned to Interrupt Line 1
  [14] TEFFL rw — Tx Event FIFO Full Line #br# 0 Interrupt source is assigned to Interrupt Line 0 #br# 1 Interrupt source is assigned to Interrupt Line 1
  [13] TEFWL rw — Tx Event FIFO Watermark Reached Line #br# 0 Interrupt source is assigned to Interrupt Line 0 #br# 1 Interrupt source is assigned to Interrupt Line 1
  [12] TEFNL rw — Tx Event FIFO New Entry Line #br# 0 Interrupt source is assigned to Interrupt Line 0 #br# 1 Interrupt source is assigned to Interrupt Line 1
  [11] TFEL rw — Tx FIFO Empty Line #br# 0 Interrupt source is assigned to Interrupt Line 0 #br# 1 Interrupt source is assigned to Interrupt Line 1
  [10] TCFL rw — Transmission Cancellation Finished Line #br# 0 Interrupt source is assigned to Interrupt Line 0 #br# 1 Interrupt source is assigned to Interrupt Line 1
  [9] TCL rw — Transmission Completed Line #br# 0 Interrupt source is assigned to Interrupt Line 0 #br# 1 Interrupt source is assigned to Interrupt Line 1
  [8] HPML rw — High Priority Message Line #br# 0 Interrupt source is assigned to Interrupt Line 0 #br# 1 Interrupt source is assigned to Interrupt Line 1
  [7] RF1LL rw — Rx FIFO 1 Message Lost Line #br# 0 Interrupt source is assigned to Interrupt Line 0 #br# 1 Interrupt source is assigned to Interrupt Line 1
  [6] RF1FL rw — Rx FIFO 1 Full Line #br# 0 Interrupt source is assigned to Interrupt Line 0 #br# 1 Interrupt source is assigned to Interrupt Line 1
  [5] RF1WL rw — Rx FIFO 1 Watermark Reached Line #br# 0 Interrupt source is assigned to Interrupt Line 0 #br# 1 Interrupt source is assigned to Interrupt Line 1
  [4] RF1NL rw — Rx FIFO 1 New Message Line #br# 0 Interrupt source is assigned to Interrupt Line 0 #br# 1 Interrupt source is assigned to Interrupt Line 1
  [3] RF0LL rw — Rx FIFO 0 Message Lost Line #br# 0 Interrupt source is assigned to Interrupt Line 0 #br# 1 Interrupt source is assigned to Interrupt Line 1
  [2] RF0FL rw — Rx FIFO 0 Full Line #br# 0 Interrupt source is assigned to Interrupt Line 0 #br# 1 Interrupt source is assigned to Interrupt Line 1
  [1] RF0WL rw — Rx FIFO 0 Watermark Reached Line #br# 0 Interrupt source is assigned to Interrupt Line 0 #br# 1 Interrupt source is assigned to Interrupt Line 1
  [0] RF0NL rw — Rx FIFO 0 New Message Line #br# 0 Interrupt source is assigned to Interrupt Line 0 #br# 1 Interrupt source is assigned to Interrupt Line 1
